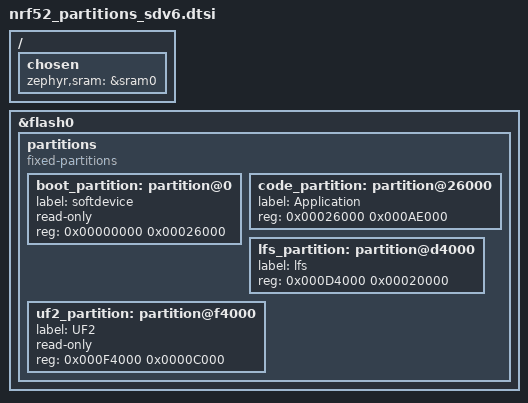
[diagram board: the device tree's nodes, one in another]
/*
 * SPDX-License-Identifier: MIT
 * nRF52840 partition layout — SoftDevice s140 v6 + UF2 bootloader
 *
 * See nrf52_partitions_sdv7.dtsi for full include guide.
 * Use THIS file instead of sdv7 when the board's UF2 bootloader
 * bundles SoftDevice s140 v6.x (app starts at 0x26000).
 *
 * Boards: RAK4631, ThinkNode M6
 *
 * Usage in board overlay:
 *   /delete-node/ &boot_partition;
 *   /delete-node/ &slot0_partition;
 *   /delete-node/ &slot1_partition;
 *   /delete-node/ &storage_partition;
 *   #include "../../common/nrf52_partitions_sdv6.dtsi"
 *
 * Memory map (1MB internal flash):
 *   0x00000 - 0x26000  (152KB) SoftDevice s140 v6 (reserved)
 *   0x26000 - 0xD4000  (696KB) Application
 *   0xD4000 - 0xF4000  (128KB) LittleFS (/lfs automount)
 *   0xF4000 - 0x100000 (48KB)  UF2 bootloader (reserved)
 */

/ {
	chosen {
		/* nRF52840 SoC DTSI defines sram0 but does NOT set zephyr,sram
		 * in chosen. The upstream nrf52840_partition.dtsi provides it,
		 * but custom boards that include this file directly (without
		 * nrf52840_partition.dtsi) would get RAM = 0 in the linker
		 * script, causing "region RAM overflowed" on the first build.
		 * Set it here so all boards using this DTSI get it for free. */
		zephyr,sram = &sram0;
	};
};

&flash0 {
	partitions {
		compatible = "fixed-partitions";
		#address-cells = <1>;
		#size-cells = <1>;

		/* SoftDevice s140 v6.1.1 — 152KB (reserved, managed by bootloader) */
		boot_partition: partition@0 {
			label = "softdevice";
			read-only;
			reg = <0x00000000 0x00026000>;
		};

		/* Application — 696KB */
		code_partition: partition@26000 {
			label = "Application";
			reg = <0x00026000 0x000AE000>;
		};

		/* LittleFS — 128KB: identity, prefs, contacts, channels, blobs */
		lfs_partition: partition@d4000 {
			label = "lfs";
			reg = <0x000D4000 0x00020000>;
		};

		/* UF2 bootloader — 48KB (reserved) */
		uf2_partition: partition@f4000 {
			label = "UF2";
			read-only;
			reg = <0x000F4000 0x0000C000>;
		};
	};
};

/* LittleFS /lfs automount */
#include "filesystem.dtsi"
